# EMU_CM register map
Vendor: Texas Instruments
Peripheral module from a debugger description file (folder omap34xx).
Registers are 32-bit, access per field, reset values left out (the file's numbers can be read two ways) unless marked. A register's access mark holds for its fields unless they carry their own. Offsets are as the file gives them; lines under a group give offsets from that group; [hi:lo] are bit positions; {n}, {i} and the like mark numbered series; 'fields as' and 'values as' point back to an identical list; <NAME> marks a mode.

## EMU_CM
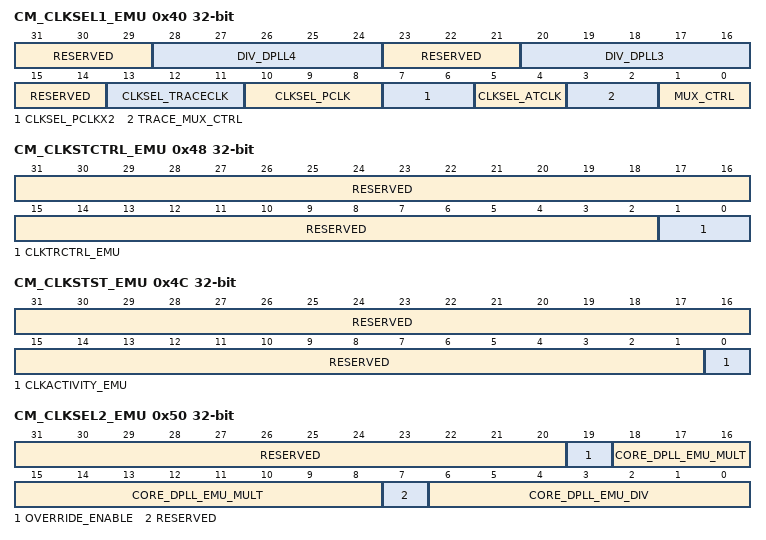
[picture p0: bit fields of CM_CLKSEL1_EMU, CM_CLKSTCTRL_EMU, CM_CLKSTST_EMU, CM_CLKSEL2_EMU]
0x40 CM_CLKSEL1_EMU — Modules clock selection.
  [31:29] RESERVED ro — Write 0s for future compatibility. Read returns 0.
  [28:24] DIV_DPLL4 rw — DPLL4 M6 clock divider factor (1 up to 16); Other enums: Reserved
    {v}=EMU_PER_ALWON_CLK is DPLL4 clock divided by {v} (v=1..16)
  [23:21] RESERVED ro — Write 0s for future compatibility. Read returns 0.
  [20:16] DIV_DPLL3 rw — DPLL3_M3X2 clock divider factor (1 up to 16); Other enums: Reserved
    {v}=EMU_CORE_ALWON_CLK is DPLL3 clock divided by {v} (v=1..16)
  [15:14] RESERVED ro — Write 0s for future compatibility. Read returns 0.
  [13:11] CLKSEL_TRACECLK rw — Selects the TRACE clock; Other enums: Reserved
    1=TRACECLK.FCLK is the selected TRACE source clock divided by 1; 2=TRACECLK.FCLK is the selected TRACE source clock divided by 2; 4=TRACECLK.FCLK is the selected TRACE source clock divided by 4
  [10:8] CLKSEL_PCLK rw — Selects the PCLK clock; Other enums: Reserved
    2=PCLK.FCLK is the selected PCLK source clock divided by 2; 3=PCLK.FCLK is the selected PCLK source clock divided by 3; 4=PCLK.FCLK is the selected PCLK source clock divided by 4; 6=PCLK.FCLK is the selected PCLK source clock divided by 6
  [7:6] CLKSEL_PCLKX2 rw — Selects the PCLKx2 clock; Other enums: Reserved
    1=PCLKx2.FCLK is the selected PCLK source clock divided by 1; 2=PCLKx2.FCLK is the selected PCLK source clock divided by 2; 3=PCLKx2.FCLK is the selected PCLK source clock divided by 3
  [5:4] CLKSEL_ATCLK rw — Selects the ATCLK clock; Other enums: Reserved
    1=ATCLK.FCLK is the selected ATCLK source clock divided by 1; 2=ATCLK.FCLK is the selected ATCLK source clock divided by 2
  [3:2] TRACE_MUX_CTRL rw — Selection of TRACECLK.FCLK source clock
    0=TRACE source clock is SYS_CLK; 1=TRACE source clock is EMU_CORE_ALWON_CLK; 2=TRACE source clock is EMU_PER_ALWON clock; 3=TRACE source clock is EMU_MPU_ALWON clock
  [1:0] MUX_CTRL rw — Selection of ATCLK.FCLK, PCLK.FCLK and PCLKx2.FCLK source clock
    0=ATCLK, PCLK and PCLKx2 source clock is SYS_CLK; 1=ATCLK, PCLK and PCLKx2 source clock is EMU_CORE_ALWON_CLK; 2=ATCLK, PCLK and PCLKx2 source clock is EMU_PER_ALWON clock; 3=ATCLK, PCLK and PCLKx2 source clock is EMU_MPU_ALWON_CLK
0x48 CM_CLKSTCTRL_EMU — This register allows to enable or disable SW and HW supervised transition between ACTIVE and INACTIVE states.
  [31:2] RESERVED ro — Write 0s for future compatibility. Read returns 0.
  [1:0] CLKTRCTRL_EMU rw — Controls the clock state transition of the EMULATION clock domain.
    1=Start a software supervised sleep transition on the domain; 2=Start a software supervised wake-up transition on the domain or maintain emulation domain active. (force wakeup has to be kept asserted to keep Emulation domain ON); 3=Automatic transition is enabled. Transition is supervised by the HardWare.
0x4C CM_CLKSTST_EMU ro — This register provides a status on the clock activity in the domain (depends on the selected source clock).
  [31:1] RESERVED — Write 0s for future compatibility. Read returns 0.
  [0] CLKACTIVITY_EMU — Clock activity status (depends on the selected source clock)
    0=No domain clock activity; 1=Domain clock is active
0x50 CM_CLKSEL2_EMU — This register provides override controls over the DPLL3.
  [31:20] RESERVED ro — Write 0s for future compatibility. Read returns 0.
  [19] OVERRIDE_ENABLE rw — This bit allows to enable or disable the emulation override controls
    0=The emulation override controls are disabled; 1=The emulation override controls are enabled
  [18:8] CORE_DPLL_EMU_MULT rw — DPLL3 override multiplier factor (0 to 2047)
  [7] RESERVED ro — Write 0s for future compatibility. Read returns 0.
  [6:0] CORE_DPLL_EMU_DIV rw — DPLL3 override divider factor (0 to 127)
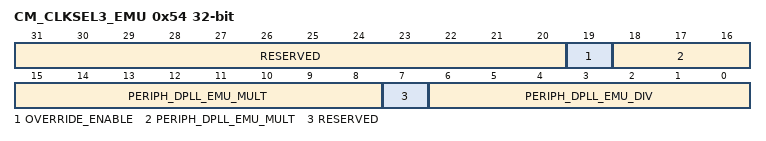
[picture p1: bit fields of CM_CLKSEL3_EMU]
0x54 CM_CLKSEL3_EMU — This register provides override controls over the PERIPHERAL DPLL.
  [31:20] RESERVED ro — Write 0s for future compatibility. Read returns 0.
  [19] OVERRIDE_ENABLE rw — This bit allows to enable or disable the emulation override controls
    values as CM_CLKSEL2_EMU.OVERRIDE_ENABLE
  [18:8] PERIPH_DPLL_EMU_MULT rw — DPLL4 override multiplier factor (0 to 2047)
  [7] RESERVED ro — Write 0s for future compatibility. Read returns 0.
  [6:0] PERIPH_DPLL_EMU_DIV rw — DPLL4 override divider factor (0 to 127)
